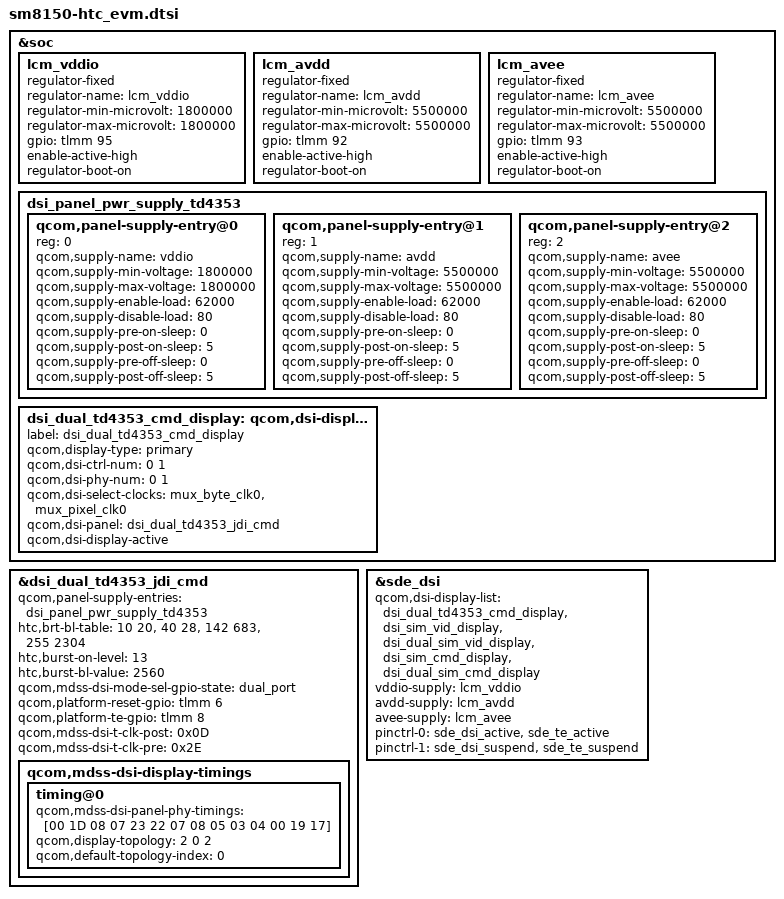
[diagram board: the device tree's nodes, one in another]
/*
 * sm8150-htc_evm: configs of sm8150 HTC EVM projects
 */

#include "dsi-panel-td4353-jdi-wqhd-cmd.dtsi"

&soc {
	lcm_vddio: lcm_vddio {
		compatible = "regulator-fixed";
		regulator-name = "lcm_vddio";
		regulator-min-microvolt = <1800000>;
		regulator-max-microvolt = <1800000>;
		gpio = <&tlmm 95 0>;
		enable-active-high;
		regulator-boot-on;
//		regulator-always-on;
	};
	lcm_avdd: lcm_avdd {
		compatible = "regulator-fixed";
		regulator-name = "lcm_avdd";
		regulator-min-microvolt = <5500000>;
		regulator-max-microvolt = <5500000>;
		gpio = <&tlmm 92 0>;
		enable-active-high;
		regulator-boot-on;
	};
	lcm_avee: lcm_avee {
		compatible = "regulator-fixed";
		regulator-name = "lcm_avee";
		regulator-min-microvolt = <5500000>;
		regulator-max-microvolt = <5500000>;
		gpio = <&tlmm 93 0>;
		enable-active-high;
		regulator-boot-on;
	};
};


&soc {
	dsi_panel_pwr_supply_td4353: dsi_panel_pwr_supply_td4353 {
		#address-cells = <1>;
		#size-cells = <0>;
		qcom,panel-supply-entry@0 {
			reg = <0>;
			qcom,supply-name = "vddio";
			qcom,supply-min-voltage = <1800000>;
			qcom,supply-max-voltage = <1800000>;
			qcom,supply-enable-load = <62000>;
			qcom,supply-disable-load = <80>;
			qcom,supply-pre-on-sleep = <0>;
			qcom,supply-post-on-sleep = <5>;
			qcom,supply-pre-off-sleep = <0>;
			qcom,supply-post-off-sleep = <5>;
		};
		qcom,panel-supply-entry@1 {
			reg = <1>;
			qcom,supply-name = "avdd";
			qcom,supply-min-voltage = <5500000>;
			qcom,supply-max-voltage = <5500000>;
			qcom,supply-enable-load = <62000>;
			qcom,supply-disable-load = <80>;
			qcom,supply-pre-on-sleep = <0>;
			qcom,supply-post-on-sleep = <5>;
			qcom,supply-pre-off-sleep = <0>;
			qcom,supply-post-off-sleep = <5>;
		};
		qcom,panel-supply-entry@2 {
			reg = <2>;
			qcom,supply-name = "avee";
			qcom,supply-min-voltage = <5500000>;
			qcom,supply-max-voltage = <5500000>;
			qcom,supply-enable-load = <62000>;
			qcom,supply-disable-load = <80>;
			qcom,supply-pre-on-sleep = <0>;
			qcom,supply-post-on-sleep = <5>;
			qcom,supply-pre-off-sleep = <0>;
			qcom,supply-post-off-sleep = <5>;
		};
	};

	dsi_dual_td4353_cmd_display: qcom,dsi-display@19 {
		label = "dsi_dual_td4353_cmd_display";
		qcom,display-type = "primary";

		qcom,dsi-ctrl-num = <0 1>;
		qcom,dsi-phy-num = <0 1>;
		qcom,dsi-select-clocks = "mux_byte_clk0", "mux_pixel_clk0";

		qcom,dsi-panel = <&dsi_dual_td4353_jdi_cmd>;

		qcom,dsi-display-active;
	};
};

&dsi_dual_td4353_jdi_cmd {
	qcom,panel-supply-entries = <&dsi_panel_pwr_supply_td4353>;
//	htc,mdss-dsi-bl-backlight = <&lp8556_bl>;
//	qcom,mdss-dsi-bl-pmic-control-type = "bl_ctrl_i2c";
//	qcom,mdss-dsi-bl-min-level = <1>;
//	qcom,mdss-dsi-bl-max-level = <255>;
	htc,brt-bl-table = <10 20>, <40 28>, <142 683>, <255 2304>;
	htc,burst-on-level = <13>;
	htc,burst-bl-value = <2560>;
	qcom,mdss-dsi-mode-sel-gpio-state = "dual_port";
	qcom,platform-reset-gpio = <&tlmm 6 0>;
	qcom,platform-te-gpio = <&tlmm 8 0>;

	qcom,mdss-dsi-t-clk-post = <0x0D>;
	qcom,mdss-dsi-t-clk-pre = <0x2E>;
	qcom,mdss-dsi-display-timings {
		timing@0 {
			qcom,mdss-dsi-panel-phy-timings = [00 1D 08 07 23 22 07
				08 05 03 04 00 19 17];
			qcom,display-topology = <2 0 2>;
			qcom,default-topology-index = <0>;
		};
	};
};

&sde_dsi {
	qcom,dsi-display-list =
		<&dsi_dual_td4353_cmd_display
		&dsi_sim_vid_display
		&dsi_dual_sim_vid_display
		&dsi_sim_cmd_display
		&dsi_dual_sim_cmd_display>;

	vddio-supply = <&lcm_vddio>;
	avdd-supply = <&lcm_avdd>;
	avee-supply = <&lcm_avee>;

	pinctrl-names = "panel_active", "panel_suspend";
	pinctrl-0 = <&sde_dsi_active &sde_te_active>;
	pinctrl-1 = <&sde_dsi_suspend &sde_te_suspend>;
};
